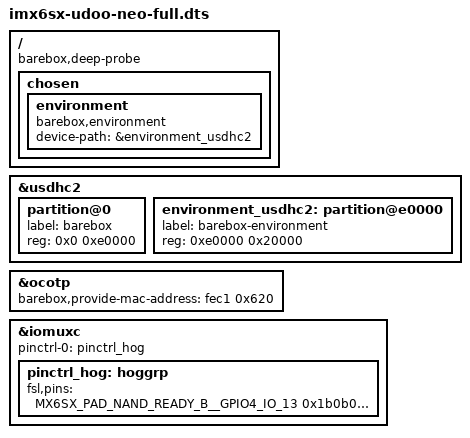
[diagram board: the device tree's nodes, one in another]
#include <arm/nxp/imx/imx6sx-udoo-neo-full.dts>
#include "imx6sx.dtsi"

/ {
	barebox,deep-probe;
	/delete-node/ memory@80000000;

	chosen {
		environment {
			compatible = "barebox,environment";
			device-path = &environment_usdhc2;
		};
	};
};

&usdhc2 {
	#address-cells = <1>;
	#size-cells = <1>;

	partition@0 {
		label = "barebox";
		reg = <0x0 0xe0000>;
	};

	environment_usdhc2: partition@e0000 {
		label = "barebox-environment";
		reg = <0xe0000 0x20000>;
	};
};

&ocotp {
	barebox,provide-mac-address = <&fec1 0x620>;
};

&iomuxc {
	pinctrl-names = "default";
	pinctrl-0 = <&pinctrl_hog>;

	pinctrl_hog: hoggrp {
		fsl,pins = <
			MX6SX_PAD_NAND_READY_B__GPIO4_IO_13	0x1b0b0
			MX6SX_PAD_NAND_ALE__GPIO4_IO_0		0x1b0b0
		>;
	};
};
